# earlgrey register map
Vendor: lowRISC; File version: 0.1
CPU: ibex rev01, little endian, no MPU, no FPU, VTOR, 2 interrupt priority bits, 2 interrupts
Registers are 32-bit, read-write, no defined reset value unless marked. A register's access mark holds for its fields unless they carry their own. Offsets are from the block's base; [hi:lo] are bit positions; 'fields as' and 'values as' point back to an identical list.

## RV_CORE_IBEX — Dual-core lockstep 32-bit RISC-V processor running application and control software
Base 0x411F0000
0x40 SW_RECOV_ERR — Software recoverable error
  [3:0] VAL — Software recoverable alert.When set to any value other than kMultiBitBool4False, a recoverable alert is sent.Once the alert is sent, the field is then reset to kMultiBitBool4False.
0x44 SW_FATAL_ERR — Software fatal error
  [3:0] VAL — Software fatal alert.When set to any value other than kMultiBitBool4False, a fatal alert is sent.Note, this field once cleared cannot be set and will continuously cause alert events.
0x48 IBUS_REGWEN_0 — Ibus address control regwen.
  [0] EN — Ibus address controls write enable. Once set to 0, it can longer be configured to 1
0x4C IBUS_REGWEN_1 — Ibus address control regwen.
  fields as IBUS_REGWEN_0
0x50 IBUS_ADDR_EN_0 — Enable Ibus address matching
  [0] EN — Enable ibus address matching.
0x54 IBUS_ADDR_EN_1 — Enable Ibus address matching
  [0] EN — Enable ibus address matching.
0x58 IBUS_ADDR_MATCHING_0 — Matching region programming for ibus. The value programmed is done at power-of-2 alignment. For example, if the intended matching region is 0x8000_0000 to 0x8000_FFFF, the value programmed is 0x8000_7FFF. The value programmed can be determined from the translation granule. Assume the user wishes to translate a specific 64KB block to a different address: 64KB has a hex value of 0x10000. Subtract 1 from this value and then right shift by one to obtain 0x7FFF. This value is then logically OR'd with the upper address bits that would select which 64KB to translate. In this example, the user wishes to translate the 0x8000-th 64KB block. The value programmed is then 0x8000_7FFF. If the user were to translate the 0x8001-th 64KB block, the value programmed would be 0x8001_7FFF.
  [31:0] VAL — Matching region value
0x5C IBUS_ADDR_MATCHING_1 — Matching region programming for ibus. The value programmed is done at power-of-2 alignment. For example, if the intended matching region is 0x8000_0000 to 0x8000_FFFF, the value programmed is 0x8000_7FFF. The value programmed can be determined from the translation granule. Assume the user wishes to translate a specific 64KB block to a different address: 64KB has a hex value of 0x10000. Subtract 1 from this value and then right shift by one to obtain 0x7FFF. This value is then logically OR'd with the upper address bits that would select which 64KB to translate. In this example, the user wishes to translate the 0x8000-th 64KB block. The value programmed is then 0x8000_7FFF. If the user were to translate the 0x8001-th 64KB block, the value programmed would be 0x8001_7FFF.
  [31:0] VAL — Matching region value
0x60 IBUS_REMAP_ADDR_0 — The remap address after a match has been made. The remap bits apply only to top portion of address bits not covered by the matching region. For example, if the translation region is 64KB, the remapped address applies only to the upper address bits that select which 64KB to be translated.
  [31:0] VAL — Remap addr value
0x64 IBUS_REMAP_ADDR_1 — The remap address after a match has been made. The remap bits apply only to top portion of address bits not covered by the matching region. For example, if the translation region is 64KB, the remapped address applies only to the upper address bits that select which 64KB to be translated.
  [31:0] VAL — Remap addr value
0x68 DBUS_REGWEN_0 — Dbus address control regwen.
  fields as IBUS_REGWEN_0
0x6C DBUS_REGWEN_1 — Dbus address control regwen.
  fields as IBUS_REGWEN_0
0x70 DBUS_ADDR_EN_0 — Enable dbus address matching
  [0] EN — Enable dbus address matching.
0x74 DBUS_ADDR_EN_1 — Enable dbus address matching
  [0] EN — Enable dbus address matching.
0x78 DBUS_ADDR_MATCHING_0 — See !!IBUS_ADDR_MATCHING_0 for detailed description.
  [31:0] VAL — Matching region value
0x7C DBUS_ADDR_MATCHING_1 — See !!IBUS_ADDR_MATCHING_0 for detailed description.
  [31:0] VAL — Matching region value
0x80 DBUS_REMAP_ADDR_0 — See !!IBUS_REMAP_ADDR_0 for a detailed description.
  [31:0] VAL — Remap addr value
0x84 DBUS_REMAP_ADDR_1 — See !!IBUS_REMAP_ADDR_0 for a detailed description.
  [31:0] VAL — Remap addr value
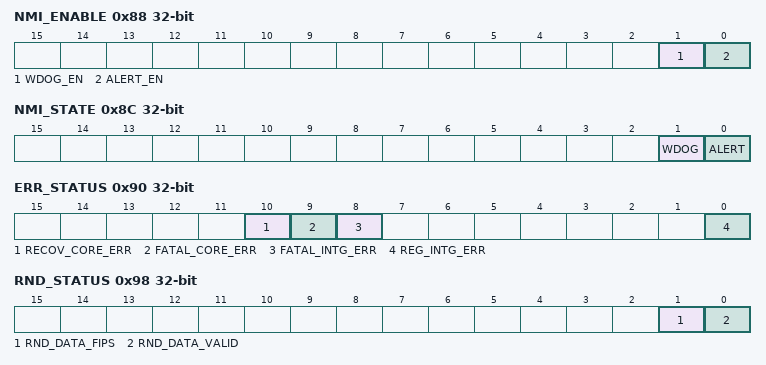
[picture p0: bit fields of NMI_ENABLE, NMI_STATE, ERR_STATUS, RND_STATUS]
0x88 NMI_ENABLE — Enable mask for NMI.Once an enable mask is set, it cannot be disabled.
  [1] WDOG_EN — Enable mask for watchdog NMI
  [0] ALERT_EN — Enable mask for alert NMI
0x8C NMI_STATE — Current NMI state
  [1] WDOG — Current state for watchdog NMI
  [0] ALERT — Current state for alert NMI
0x90 ERR_STATUS — error status
  [10] RECOV_CORE_ERR — rv_core_ibex detected a recoverable internal error(``alert_minor`` from Ibex seen)
  [9] FATAL_CORE_ERR — rv_core_ibex detected a fatal internal error(``alert_major_internal_o`` from Ibex seen)
  [8] FATAL_INTG_ERR — rv_core_ibex detected a response integrity error
  [0] REG_INTG_ERR — rv_core_ibex_peri detected a register transmission integrity error
0x94 RND_DATA ro — Random data from EDN
  [31:0] DATA — Random bits taken from the EDN. !!RND_STATUS.RND_DATA_VALIDindicates if this data is valid. When valid, reading from thisregister invalidates the data and requests new data from the EDN.The register becomes valid again when the EDN provides new data.When invalid the register value will read as 0x0 with an EDNrequest for new data pending. Upon reset the data will be invalidwith a new EDN request pending.
0x98 RND_STATUS ro — Status of random data in !!RND_DATA
  [1] RND_DATA_FIPS — When !!RND_STATUS.RND_DATA_VALID is 1, this bit indicates whether!!RND_DATA is fips quality.When !!RND_STATUS.RND_DATA_VALID is 0, this bit has no meaning.
  [0] RND_DATA_VALID — When set, the data in !!RND_DATA is valid. When clear an EDNrequest for new data for !!RND_DATA is pending.
0x9C FPGA_INFO ro — FPGA build timestamp info.This register only contains valid data for fpga, for all other variants it is simply 0.
  [31:0] VAL — FPGA build timestamp information.
